AUTOSAR XML (schema 4-2-2)
package /Components
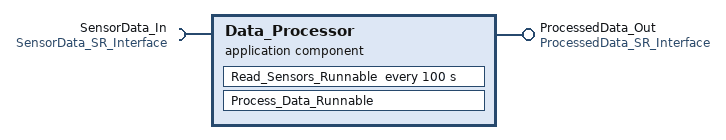
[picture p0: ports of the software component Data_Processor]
  application sw component type Data_Processor
    provide port ProcessedData_Out: provided-interface=ProcessedData_SR_Interface
    require port SensorData_In: required-interface=SensorData_SR_Interface
    behavior Data_Processor_Behavior
      data received event RawTemp_Received_Event: start-on-event=Read_Sensors_Runnable
      timing event Processor_Periodic_Check: start-on-event=Read_Sensors_Runnable, period=100
      runnable Process_Data_Runnable: minimum-start-interval=0.02, symbol=Data_Processor_Process_Data_Runnable
        data-receive-point-by-arguments:
          access RawTemp{1..3}_Access: accessed-variable=SensorData_In.RawTemp{1..3}
        data-send-points:
          access CalibratedTemp{1..3}_Send: accessed-variable=ProcessedData_Out.CalibratedTemp{1..3}
